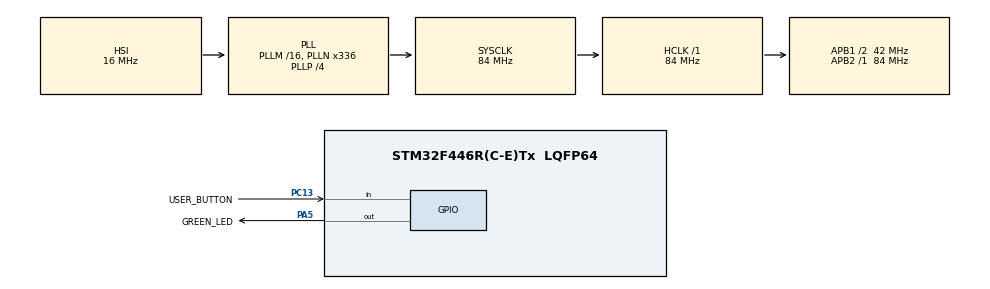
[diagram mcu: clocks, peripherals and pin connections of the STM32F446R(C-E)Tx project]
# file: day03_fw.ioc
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Mcu.Family=STM32F4
Mcu.Name=STM32F446R(C-E)Tx
Mcu.Package=LQFP64
NVIC.PriorityGroup=NVIC_PRIORITYGROUP_0
PA13.GPIO_Label=TMS
PA13.Mode=Serial_Wire
PA13.Signal=SYS_JTMS-SWDIO
PA14.GPIO_Label=TCK
PA14.Mode=Serial_Wire
PA14.Signal=SYS_JTCK-SWCLK
PA5.GPIO_Label=GREEN_LED
PA5.Signal=GPIO_Output
PB3.GPIO_Label=SWO
PB3.Signal=SYS_JTDO-SWO
PC13.GPIO_Label=USER_BUTTON
PC13.Signal=GPIO_Input
ProjectManager.HeapSize=0x200
ProjectManager.StackSize=0x400
ProjectManager.TargetToolchain=STM32CubeIDE
RCC.48MHZClocksFreq_Value=84000000
RCC.AHBFreq_Value=84000000
RCC.APB1CLKDivider=RCC_HCLK_DIV2
RCC.APB1Freq_Value=42000000
RCC.APB1TimFreq_Value=84000000
RCC.APB2Freq_Value=84000000
RCC.APB2TimFreq_Value=84000000
RCC.CortexFreq_Value=84000000
RCC.FLatency-AdvancedSettings=FLASH_LATENCY_2
RCC.HCLKFreq_Value=84000000
RCC.HSE_VALUE=8000000
RCC.HSI_VALUE=16000000
RCC.PLLN=336
RCC.PLLP=RCC_PLLP_DIV4
RCC.SYSCLKFreq_VALUE=84000000
RCC.SYSCLKSource=RCC_SYSCLKSOURCE_PLLCLK
RCC.USBFreq_Value=168000000
RCC.VCOOutputFreq_Value=336000000
board=NUCLEO-F446RE

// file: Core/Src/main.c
/* USER CODE BEGIN Header */
/**
 ******************************************************************************
 * @file           : main.c
 * @brief          : Main program body
 ******************************************************************************
 * @attention
 *
 * Copyright (c) 2025 STMicroelectronics.
 * All rights reserved.
 *
 * This software is licensed under terms that can be found in the LICENSE file
 * in the root directory of this software component.
 * If no LICENSE file comes with this software, it is provided AS-IS.
 *
 ******************************************************************************
 */
/* USER CODE END Header */
#include "main.h"
#include "gpio.h"
#include <stdbool.h>

/* USER CODE BEGIN PV */
static bool toggleMode = false;
static uint32_t lastDebounceTime = 0;
static GPIO_PinState lastButtonState = GPIO_PIN_SET;
static GPIO_PinState buttonStableState = GPIO_PIN_SET;
/* USER CODE END PV */

void SystemClock_Config(void);
/* USER CODE BEGIN PFP */
/**
 * @brief  Initializes LED GPIO.
 * @param  none
 * @retval none
 */
void Blink_LED_Init(void);

/**
 * @brief  Toggles LED at 1 Hz.
 * @param  none
 * @retval none
 * @constraints: Use HAL_Delay(500); no busy loops.
 */
void Blink_LED_Task(void);

/**
 * @brief  Initializes Button GPIO.
 * @param  none
 * @retval none
 */
void Button_Init(void);

/**
 * @brief  Reads button with 50 ms debounce and toggles LED on press.
 * @param  none
 * @retval none
 * @constraints: Use HAL_GetTick(); compare time delta >50 ms.
 */
void Button_Task(void);
/* USER CODE END PFP */

/* USER CODE BEGIN 0 */
/**
 * @brief  Initializes LED GPIO.
 * @param  none
 * @retval none
 */
void Blink_LED_Init(void) {
	// GPIO already setup by MX_GPIO_Init().
	// Only need to choose initial state.
	HAL_GPIO_WritePin(GREEN_LED_GPIO_Port, GREEN_LED_Pin, GPIO_PIN_RESET);
}

/**
 * @brief  Toggles LED at 1 Hz.
 * @param  none
 * @retval none
 * @constraints: Use HAL_Delay(500); no busy loops.
 */
void Blink_LED_Task(void) {
	HAL_GPIO_TogglePin(GREEN_LED_GPIO_Port, GREEN_LED_Pin);
	HAL_Delay(500);
}

/**
 * @brief  Initializes Button GPIO.
 * @param  none
 * @retval none
 */
void Button_Init(void) {
	// Already done by MX_GPIO_Init() so nothing needs to be done here.
}

/**
 * @brief  Reads button with 50 ms debounce and toggles LED on press.
 * @param  none
 * @retval none
 * @constraints: Use HAL_GetTick(); compare time delta >50 ms.
 */
void Button_Task(void) {
	GPIO_PinState buttonState = HAL_GPIO_ReadPin(USER_BUTTON_GPIO_Port, USER_BUTTON_Pin);

	if (buttonState != lastButtonState) {
		lastButtonState = buttonState;
		lastDebounceTime = HAL_GetTick();
	} else if ((uint32_t)(HAL_GetTick() - lastDebounceTime) >= 50U) {
		if (buttonState != buttonStableState) {
			buttonStableState = buttonState;

			if (buttonStableState == GPIO_PIN_RESET) {
				toggleMode = true;
				HAL_GPIO_TogglePin(GREEN_LED_GPIO_Port, GREEN_LED_Pin);
			}
		}
	}
}
/* USER CODE END 0 */

int main(void)
{

	/* MCU Configuration--------------------------------------------------------*/

	/* Reset of all peripherals, Initializes the Flash interface and the Systick. */
	HAL_Init();

	/* Configure the system clock */
	SystemClock_Config();

	/* Initialize all configured peripherals */
	MX_GPIO_Init();

	/* Infinite loop */
	/* USER CODE BEGIN WHILE */
	while (1)
	{
		if (!toggleMode) {
			Blink_LED_Task(); // toggle LED then delay 1hz
		}
		Button_Task(); // read + debounce (toggle LED on press)
		/* USER CODE END WHILE */

	}
}

void SystemClock_Config(void)
{
	RCC_OscInitTypeDef RCC_OscInitStruct = {0};
	RCC_ClkInitTypeDef RCC_ClkInitStruct = {0};

	/** Configure the main internal regulator output voltage
	 */
	__HAL_RCC_PWR_CLK_ENABLE();
	__HAL_PWR_VOLTAGESCALING_CONFIG(PWR_REGULATOR_VOLTAGE_SCALE3);

	/** Initializes the RCC Oscillators according to the specified parameters
	 * in the RCC_OscInitTypeDef structure.
	 */
	RCC_OscInitStruct.OscillatorType = RCC_OSCILLATORTYPE_HSI;
	RCC_OscInitStruct.HSIState = RCC_HSI_ON;
	RCC_OscInitStruct.HSICalibrationValue = RCC_HSICALIBRATION_DEFAULT;
	RCC_OscInitStruct.PLL.PLLState = RCC_PLL_ON;
	RCC_OscInitStruct.PLL.PLLSource = RCC_PLLSOURCE_HSI;
	RCC_OscInitStruct.PLL.PLLM = 16;
	RCC_OscInitStruct.PLL.PLLN = 336;
	RCC_OscInitStruct.PLL.PLLP = RCC_PLLP_DIV4;
	RCC_OscInitStruct.PLL.PLLQ = 2;
	RCC_OscInitStruct.PLL.PLLR = 2;
	if (HAL_RCC_OscConfig(&RCC_OscInitStruct) != HAL_OK)
	{
		Error_Handler();
	}

	/** Initializes the CPU, AHB and APB buses clocks
	 */
	RCC_ClkInitStruct.ClockType = RCC_CLOCKTYPE_HCLK|RCC_CLOCKTYPE_SYSCLK
			|RCC_CLOCKTYPE_PCLK1|RCC_CLOCKTYPE_PCLK2;
	RCC_ClkInitStruct.SYSCLKSource = RCC_SYSCLKSOURCE_PLLCLK;
	RCC_ClkInitStruct.AHBCLKDivider = RCC_SYSCLK_DIV1;
	RCC_ClkInitStruct.APB1CLKDivider = RCC_HCLK_DIV2;
	RCC_ClkInitStruct.APB2CLKDivider = RCC_HCLK_DIV1;

	if (HAL_RCC_ClockConfig(&RCC_ClkInitStruct, FLASH_LATENCY_2) != HAL_OK)
	{
		Error_Handler();
	}
}

void Error_Handler(void)
{
	__disable_irq();
	while (1)
	{
	}
}
